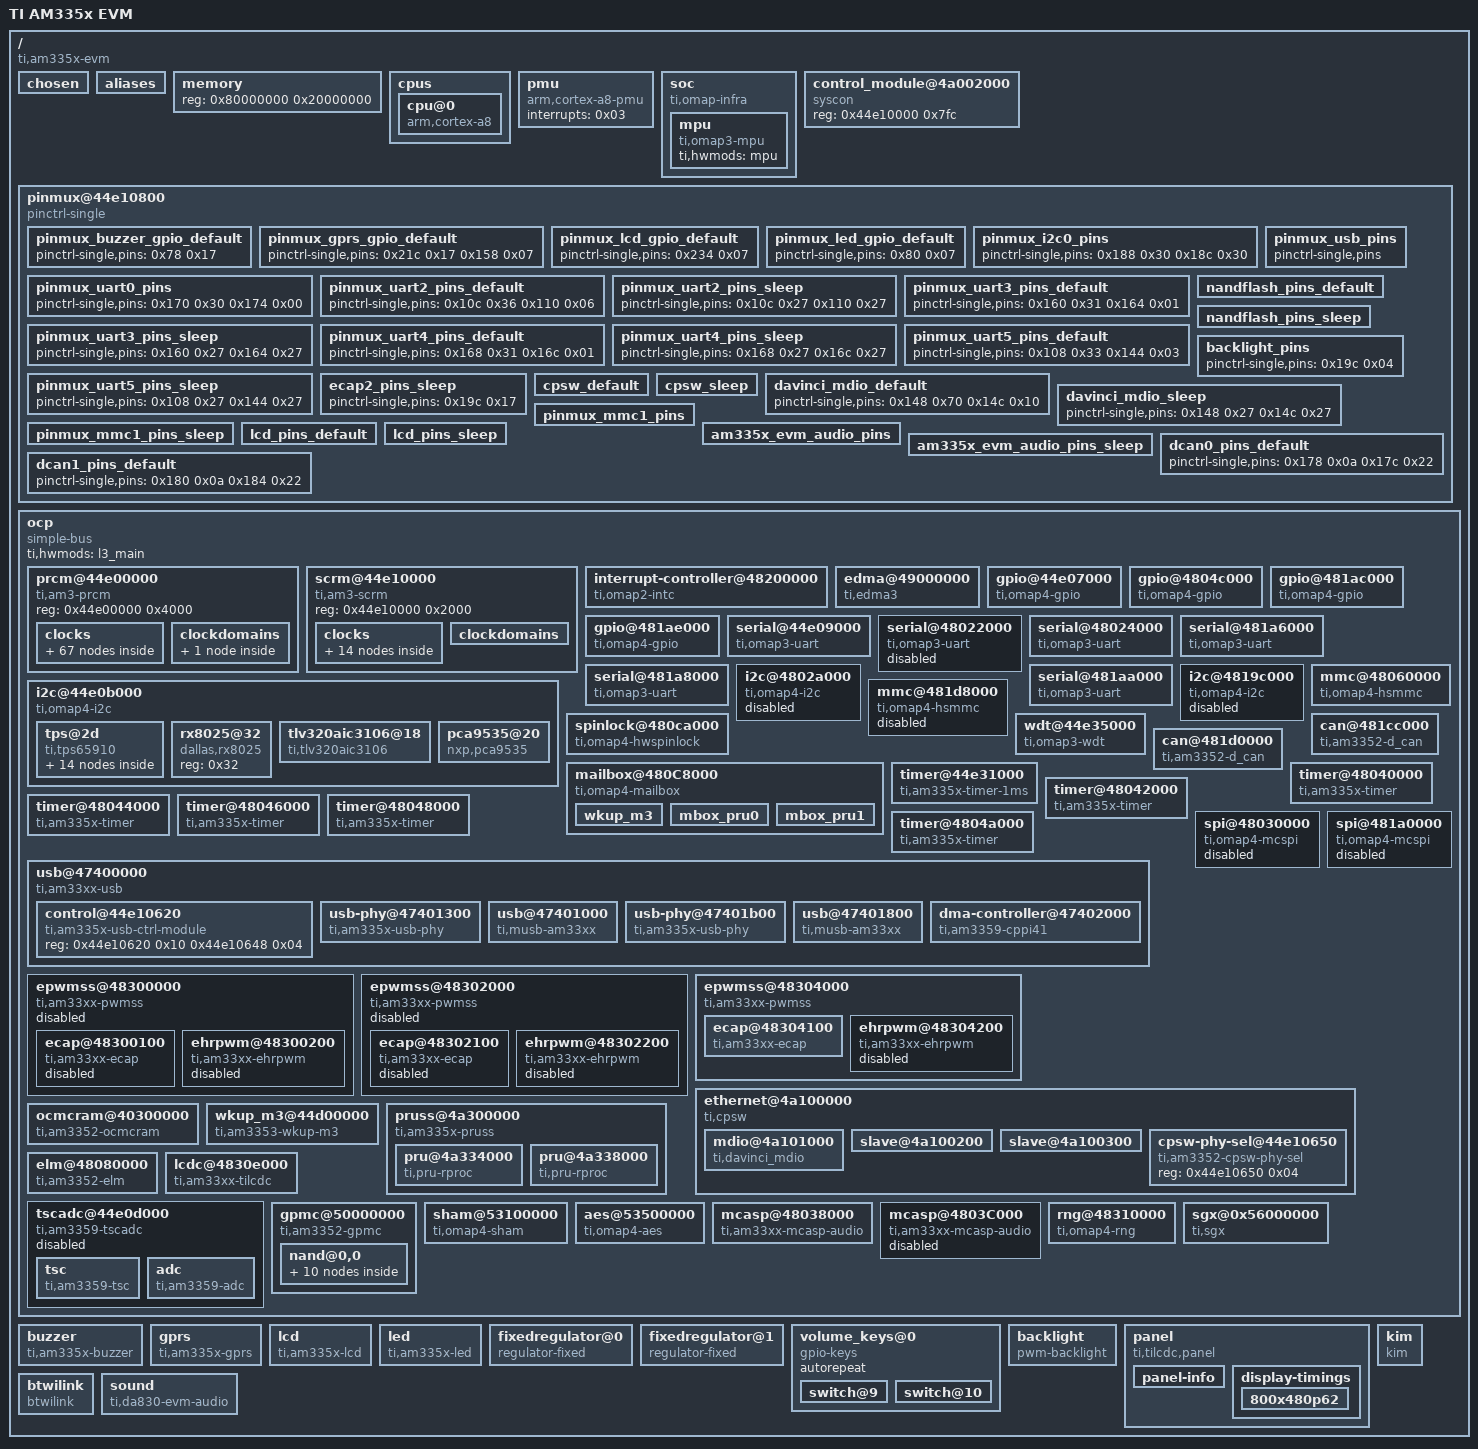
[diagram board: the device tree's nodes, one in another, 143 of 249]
/dts-v1/;

/ {
	#address-cells = <0x01>;
	#size-cells = <0x01>;
	compatible = "ti,am335x-evm", "ti,am33xx";
	interrupt-parent = <0x01>;
	model = "TI AM335x EVM";

	chosen {
	};

	aliases {
		i2c1 = "/ocp/i2c@44e0b000";
		i2c0 = "/ocp/i2c@4802a000";
		i2c2 = "/ocp/i2c@4819c000";
		serial0 = "/ocp/serial@44e09000";
		serial1 = "/ocp/serial@48022000";
		serial2 = "/ocp/serial@48024000";
		serial3 = "/ocp/serial@481a6000";
		serial4 = "/ocp/serial@481a8000";
		serial5 = "/ocp/serial@481aa000";
		d_can0 = "/ocp/can@481cc000";
		d_can1 = "/ocp/can@481d0000";
		usb0 = "/ocp/usb@47400000/usb@47401000";
		usb1 = "/ocp/usb@47400000/usb@47401800";
		phy0 = "/ocp/usb@47400000/usb-phy@47401300";
		phy1 = "/ocp/usb@47400000/usb-phy@47401b00";
		ethernet0 = "/ocp/ethernet@4a100000/slave@4a100200";
		ethernet1 = "/ocp/ethernet@4a100000/slave@4a100300";
	};

	memory {
		device_type = "memory";
		reg = <0x80000000 0x20000000>;
	};

	cpus {
		#address-cells = <0x01>;
		#size-cells = <0x00>;

		cpu@0 {
			compatible = "arm,cortex-a8";
			device_type = "cpu";
			reg = <0x00>;
			voltage-tolerance = <0x02>;
			clocks = <0x02>;
			clock-names = "cpu";
			clock-latency = <0x493e0>;
			cpu0-supply = <0x03>;
		};
	};

	pmu {
		compatible = "arm,cortex-a8-pmu";
		interrupts = <0x03>;
	};

	soc {
		compatible = "ti,omap-infra";

		mpu {
			compatible = "ti,omap3-mpu";
			ti,hwmods = "mpu";
		};
	};

	control_module@4a002000 {
		compatible = "syscon";
		reg = <0x44e10000 0x7fc>;
		linux,phandle = <0x36>;
		phandle = <0x36>;
	};

	pinmux@44e10800 {
		compatible = "pinctrl-single";
		reg = <0x44e10800 0x238>;
		#address-cells = <0x01>;
		#size-cells = <0x00>;
		pinctrl-single,register-width = <0x20>;
		pinctrl-single,function-mask = <0x7f>;

		pinmux_buzzer_gpio_default {
			pinctrl-single,pins = <0x78 0x17>;
			linux,phandle = <0x53>;
			phandle = <0x53>;
		};

		pinmux_gprs_gpio_default {
			pinctrl-single,pins = <0x21c 0x17 0x158 0x07>;
			linux,phandle = <0x55>;
			phandle = <0x55>;
		};

		pinmux_lcd_gpio_default {
			pinctrl-single,pins = <0x234 0x07>;
			linux,phandle = <0x56>;
			phandle = <0x56>;
		};

		pinmux_led_gpio_default {
			pinctrl-single,pins = <0x80 0x07>;
			linux,phandle = <0x57>;
			phandle = <0x57>;
		};

		pinmux_i2c0_pins {
			pinctrl-single,pins = <0x188 0x30 0x18c 0x30>;
			linux,phandle = <0x2e>;
			phandle = <0x2e>;
		};

		pinmux_usb_pins {
			pinctrl-single,pins;
		};

		pinmux_uart0_pins {
			pinctrl-single,pins = <0x170 0x30 0x174 0x00>;
			linux,phandle = <0x25>;
			phandle = <0x25>;
		};

		pinmux_uart2_pins_default {
			pinctrl-single,pins = <0x10c 0x36 0x110 0x06>;
			linux,phandle = <0x26>;
			phandle = <0x26>;
		};

		pinmux_uart2_pins_sleep {
			pinctrl-single,pins = <0x10c 0x27 0x110 0x27>;
			linux,phandle = <0x27>;
			phandle = <0x27>;
		};

		pinmux_uart3_pins_default {
			pinctrl-single,pins = <0x160 0x31 0x164 0x01>;
			linux,phandle = <0x28>;
			phandle = <0x28>;
		};

		pinmux_uart3_pins_sleep {
			pinctrl-single,pins = <0x160 0x27 0x164 0x27>;
			linux,phandle = <0x29>;
			phandle = <0x29>;
		};

		pinmux_uart4_pins_default {
			pinctrl-single,pins = <0x168 0x31 0x16c 0x01>;
			linux,phandle = <0x2a>;
			phandle = <0x2a>;
		};

		pinmux_uart4_pins_sleep {
			pinctrl-single,pins = <0x168 0x27 0x16c 0x27>;
			linux,phandle = <0x2b>;
			phandle = <0x2b>;
		};

		pinmux_uart5_pins_default {
			pinctrl-single,pins = <0x108 0x33 0x144 0x03>;
			linux,phandle = <0x2c>;
			phandle = <0x2c>;
		};

		pinmux_uart5_pins_sleep {
			pinctrl-single,pins = <0x108 0x27 0x144 0x27>;
			linux,phandle = <0x2d>;
			phandle = <0x2d>;
		};

		nandflash_pins_default {
			pinctrl-single,pins = <0x00 0x30 0x04 0x30 0x08 0x30 0x0c 0x30 0x10 0x30 0x14 0x30 0x18 0x30 0x1c 0x30 0x70 0x30 0x74 0x37 0x7c 0x08 0x90 0x08 0x94 0x08 0x98 0x08 0x9c 0x08>;
			linux,phandle = <0x4d>;
			phandle = <0x4d>;
		};

		nandflash_pins_sleep {
			pinctrl-single,pins = <0x00 0x27 0x04 0x27 0x08 0x27 0x0c 0x27 0x10 0x27 0x14 0x27 0x18 0x27 0x1c 0x27 0x70 0x27 0x74 0x27 0x7c 0x27 0x90 0x27 0x94 0x27 0x98 0x27 0x9c 0x27>;
			linux,phandle = <0x4e>;
			phandle = <0x4e>;
		};

		backlight_pins {
			pinctrl-single,pins = <0x19c 0x04>;
			linux,phandle = <0x3e>;
			phandle = <0x3e>;
		};

		ecap2_pins_sleep {
			pinctrl-single,pins = <0x19c 0x17>;
			linux,phandle = <0x3f>;
			phandle = <0x3f>;
		};

		cpsw_default {
			pinctrl-single,pins = <0x114 0x02 0x118 0x22 0x11c 0x02 0x120 0x02 0x124 0x02 0x128 0x02 0x12c 0x02 0x130 0x22 0x134 0x22 0x138 0x22 0x13c 0x22 0x140 0x22 0x40 0x02 0x44 0x22 0x48 0x02 0x4c 0x02 0x50 0x02 0x54 0x02 0x58 0x02 0x5c 0x22 0x60 0x22 0x64 0x22 0x68 0x22 0x6c 0x22>;
			linux,phandle = <0x42>;
			phandle = <0x42>;
		};

		cpsw_sleep {
			pinctrl-single,pins = <0x114 0x27 0x118 0x27 0x11c 0x27 0x120 0x27 0x124 0x27 0x128 0x27 0x12c 0x27 0x130 0x27 0x134 0x27 0x138 0x27 0x13c 0x27 0x140 0x27 0x40 0x27 0x44 0x27 0x48 0x27 0x4c 0x27 0x50 0x27 0x54 0x27 0x58 0x27 0x5c 0x27 0x60 0x27 0x64 0x27 0x68 0x27 0x6c 0x27>;
			linux,phandle = <0x43>;
			phandle = <0x43>;
		};

		davinci_mdio_default {
			pinctrl-single,pins = <0x148 0x70 0x14c 0x10>;
			linux,phandle = <0x44>;
			phandle = <0x44>;
		};

		davinci_mdio_sleep {
			pinctrl-single,pins = <0x148 0x27 0x14c 0x27>;
			linux,phandle = <0x45>;
			phandle = <0x45>;
		};

		pinmux_mmc1_pins {
			pinctrl-single,pins = <0xf0 0x30 0xf4 0x30 0xf8 0x30 0xfc 0x30 0x100 0x30 0x104 0x30 0x1e8 0x2f>;
			linux,phandle = <0x32>;
			phandle = <0x32>;
		};

		pinmux_mmc1_pins_sleep {
			pinctrl-single,pins = <0xf0 0x27 0xf4 0x27 0xf8 0x27 0xfc 0x27 0x100 0x27 0x104 0x27>;
			linux,phandle = <0x33>;
			phandle = <0x33>;
		};

		lcd_pins_default {
			pinctrl-single,pins = <0x20 0x01 0x24 0x01 0x28 0x01 0x2c 0x01 0x30 0x01 0x34 0x01 0x38 0x01 0x3c 0x01 0xa0 0x00 0xa4 0x00 0xa8 0x00 0xac 0x00 0xb0 0x00 0xb4 0x00 0xb8 0x00 0xbc 0x00 0xc0 0x00 0xc4 0x00 0xc8 0x00 0xcc 0x00 0xd0 0x00 0xd4 0x00 0xd8 0x00 0xdc 0x00 0xe0 0x00 0xe4 0x00 0xe8 0x00 0xec 0x00>;
			linux,phandle = <0x4b>;
			phandle = <0x4b>;
		};

		lcd_pins_sleep {
			pinctrl-single,pins = <0x20 0x27 0x24 0x27 0x28 0x27 0x2c 0x27 0x30 0x27 0x34 0x27 0x38 0x27 0x3c 0x27 0xa0 0x0f 0xa4 0x0f 0xa8 0x0f 0xac 0x0f 0xb0 0x0f 0xb4 0x0f 0xb8 0x0f 0xbc 0x0f 0xc0 0x0f 0xc4 0x0f 0xc8 0x0f 0xcc 0x0f 0xd0 0x0f 0xd4 0x0f 0xd8 0x0f 0xdc 0x0f 0xe0 0x27 0xe4 0x27 0xe8 0x27 0xec 0x27>;
			linux,phandle = <0x4c>;
			phandle = <0x4c>;
		};

		am335x_evm_audio_pins {
			pinctrl-single,pins = <0x190 0x20 0x194 0x20 0x198 0x20 0x1a8 0x20 0x1ac 0x08>;
			linux,phandle = <0x50>;
			phandle = <0x50>;
		};

		am335x_evm_audio_pins_sleep {
			pinctrl-single,pins = <0x190 0x27 0x194 0x27 0x198 0x27 0x1a8 0x27 0x1ac 0x27>;
			linux,phandle = <0x51>;
			phandle = <0x51>;
		};

		dcan0_pins_default {
			pinctrl-single,pins = <0x178 0x0a 0x17c 0x22>;
			linux,phandle = <0x37>;
			phandle = <0x37>;
		};

		dcan1_pins_default {
			pinctrl-single,pins = <0x180 0x0a 0x184 0x22>;
			linux,phandle = <0x39>;
			phandle = <0x39>;
		};
	};

	ocp {
		compatible = "simple-bus";
		#address-cells = <0x01>;
		#size-cells = <0x01>;
		ranges;
		ti,hwmods = "l3_main";

		prcm@44e00000 {
			compatible = "ti,am3-prcm";
			reg = <0x44e00000 0x4000>;

			clocks {
				#address-cells = <0x01>;
				#size-cells = <0x00>;

				clk_32768_ck {
					#clock-cells = <0x00>;
					compatible = "fixed-clock";
					clock-frequency = <0x8000>;
					linux,phandle = <0x14>;
					phandle = <0x14>;
				};

				clk_rc32k_ck {
					#clock-cells = <0x00>;
					compatible = "fixed-clock";
					clock-frequency = <0x7d00>;
					linux,phandle = <0x13>;
					phandle = <0x13>;
				};

				virt_19200000_ck {
					#clock-cells = <0x00>;
					compatible = "fixed-clock";
					clock-frequency = <0x124f800>;
					linux,phandle = <0x20>;
					phandle = <0x20>;
				};

				virt_24000000_ck {
					#clock-cells = <0x00>;
					compatible = "fixed-clock";
					clock-frequency = <0x16e3600>;
					linux,phandle = <0x21>;
					phandle = <0x21>;
				};

				virt_25000000_ck {
					#clock-cells = <0x00>;
					compatible = "fixed-clock";
					clock-frequency = <0x17d7840>;
					linux,phandle = <0x22>;
					phandle = <0x22>;
				};

				virt_26000000_ck {
					#clock-cells = <0x00>;
					compatible = "fixed-clock";
					clock-frequency = <0x18cba80>;
					linux,phandle = <0x23>;
					phandle = <0x23>;
				};

				tclkin_ck {
					#clock-cells = <0x00>;
					compatible = "fixed-clock";
					clock-frequency = <0xb71b00>;
					linux,phandle = <0x12>;
					phandle = <0x12>;
				};

				dpll_core_ck {
					#clock-cells = <0x00>;
					compatible = "ti,am3-dpll-core-clock";
					clocks = <0x04 0x04>;
					reg = <0x490 0x45c 0x468>;
					linux,phandle = <0x05>;
					phandle = <0x05>;
				};

				dpll_core_x2_ck {
					#clock-cells = <0x00>;
					compatible = "ti,am3-dpll-x2-clock";
					clocks = <0x05>;
					linux,phandle = <0x06>;
					phandle = <0x06>;
				};

				dpll_core_m4_ck {
					#clock-cells = <0x00>;
					compatible = "ti,divider-clock";
					clocks = <0x06>;
					ti,max-div = <0x1f>;
					reg = <0x480>;
					ti,index-starts-at-one;
					linux,phandle = <0x0e>;
					phandle = <0x0e>;
				};

				dpll_core_m5_ck {
					#clock-cells = <0x00>;
					compatible = "ti,divider-clock";
					clocks = <0x06>;
					ti,max-div = <0x1f>;
					reg = <0x484>;
					ti,index-starts-at-one;
					linux,phandle = <0x16>;
					phandle = <0x16>;
				};

				dpll_core_m6_ck {
					#clock-cells = <0x00>;
					compatible = "ti,divider-clock";
					clocks = <0x06>;
					ti,max-div = <0x1f>;
					reg = <0x4d8>;
					ti,index-starts-at-one;
				};

				dpll_mpu_ck {
					#clock-cells = <0x00>;
					compatible = "ti,am3-dpll-clock";
					clocks = <0x04 0x04>;
					reg = <0x488 0x420 0x42c>;
					linux,phandle = <0x02>;
					phandle = <0x02>;
				};

				dpll_mpu_m2_ck {
					#clock-cells = <0x00>;
					compatible = "ti,divider-clock";
					clocks = <0x02>;
					ti,max-div = <0x1f>;
					reg = <0x4a8>;
					ti,index-starts-at-one;
				};

				dpll_ddr_ck {
					#clock-cells = <0x00>;
					compatible = "ti,am3-dpll-no-gate-clock";
					clocks = <0x04 0x04>;
					reg = <0x494 0x434 0x440>;
					linux,phandle = <0x07>;
					phandle = <0x07>;
				};

				dpll_ddr_m2_ck {
					#clock-cells = <0x00>;
					compatible = "ti,divider-clock";
					clocks = <0x07>;
					ti,max-div = <0x1f>;
					reg = <0x4a0>;
					ti,index-starts-at-one;
					linux,phandle = <0x08>;
					phandle = <0x08>;
				};

				dpll_ddr_m2_div2_ck {
					#clock-cells = <0x00>;
					compatible = "fixed-factor-clock";
					clocks = <0x08>;
					clock-mult = <0x01>;
					clock-div = <0x02>;
				};

				dpll_disp_ck {
					#clock-cells = <0x00>;
					compatible = "ti,am3-dpll-no-gate-clock";
					clocks = <0x04 0x04>;
					reg = <0x498 0x448 0x454>;
					linux,phandle = <0x09>;
					phandle = <0x09>;
				};

				dpll_disp_m2_ck {
					#clock-cells = <0x00>;
					compatible = "ti,divider-clock";
					clocks = <0x09>;
					ti,max-div = <0x1f>;
					reg = <0x4a4>;
					ti,index-starts-at-one;
					ti,set-rate-parent;
					linux,phandle = <0x10>;
					phandle = <0x10>;
				};

				dpll_per_ck {
					#clock-cells = <0x00>;
					compatible = "ti,am3-dpll-no-gate-j-type-clock";
					clocks = <0x04 0x04>;
					reg = <0x48c 0x470 0x49c>;
					linux,phandle = <0x0a>;
					phandle = <0x0a>;
				};

				dpll_per_m2_ck {
					#clock-cells = <0x00>;
					compatible = "ti,divider-clock";
					clocks = <0x0a>;
					ti,max-div = <0x1f>;
					reg = <0x4ac>;
					ti,index-starts-at-one;
					linux,phandle = <0x0b>;
					phandle = <0x0b>;
				};

				dpll_per_m2_div4_wkupdm_ck {
					#clock-cells = <0x00>;
					compatible = "fixed-factor-clock";
					clocks = <0x0b>;
					clock-mult = <0x01>;
					clock-div = <0x04>;
				};

				dpll_per_m2_div4_ck {
					#clock-cells = <0x00>;
					compatible = "fixed-factor-clock";
					clocks = <0x0b>;
					clock-mult = <0x01>;
					clock-div = <0x04>;
				};

				cefuse_fck {
					#clock-cells = <0x00>;
					compatible = "ti,gate-clock";
					clocks = <0x04>;
					ti,bit-shift = <0x01>;
					reg = <0xa20>;
				};

				clk_24mhz {
					#clock-cells = <0x00>;
					compatible = "fixed-factor-clock";
					clocks = <0x0b>;
					clock-mult = <0x01>;
					clock-div = <0x08>;
					linux,phandle = <0x0c>;
					phandle = <0x0c>;
				};

				clkdiv32k_ck {
					#clock-cells = <0x00>;
					compatible = "fixed-factor-clock";
					clocks = <0x0c>;
					clock-mult = <0x01>;
					clock-div = <0x2dc>;
					linux,phandle = <0x0d>;
					phandle = <0x0d>;
				};

				clkdiv32k_ick {
					#clock-cells = <0x00>;
					compatible = "ti,gate-clock";
					clocks = <0x0d>;
					ti,bit-shift = <0x01>;
					reg = <0x14c>;
					linux,phandle = <0x11>;
					phandle = <0x11>;
				};

				l3_gclk {
					#clock-cells = <0x00>;
					compatible = "fixed-factor-clock";
					clocks = <0x0e>;
					clock-mult = <0x01>;
					clock-div = <0x01>;
					linux,phandle = <0x0f>;
					phandle = <0x0f>;
				};

				pruss_ocp_gclk {
					#clock-cells = <0x00>;
					compatible = "ti,mux-clock";
					clocks = <0x0f 0x10>;
					reg = <0x530>;
				};

				mmu_fck {
					#clock-cells = <0x00>;
					compatible = "ti,gate-clock";
					clocks = <0x0e>;
					ti,bit-shift = <0x01>;
					reg = <0x914>;
				};

				timer1_fck {
					#clock-cells = <0x00>;
					compatible = "ti,mux-clock";
					clocks = <0x04 0x11 0x12 0x13 0x14>;
					reg = <0x528>;
				};

				timer2_fck {
					#clock-cells = <0x00>;
					compatible = "ti,mux-clock";
					clocks = <0x12 0x04 0x11>;
					reg = <0x508>;
				};

				timer3_fck {
					#clock-cells = <0x00>;
					compatible = "ti,mux-clock";
					clocks = <0x12 0x04 0x11>;
					reg = <0x50c>;
				};

				timer4_fck {
					#clock-cells = <0x00>;
					compatible = "ti,mux-clock";
					clocks = <0x12 0x04 0x11>;
					reg = <0x510>;
				};

				timer5_fck {
					#clock-cells = <0x00>;
					compatible = "ti,mux-clock";
					clocks = <0x12 0x04 0x11>;
					reg = <0x518>;
				};

				timer6_fck {
					#clock-cells = <0x00>;
					compatible = "ti,mux-clock";
					clocks = <0x12 0x04 0x11>;
					reg = <0x51c>;
				};

				timer7_fck {
					#clock-cells = <0x00>;
					compatible = "ti,mux-clock";
					clocks = <0x12 0x04 0x11>;
					reg = <0x504>;
				};

				usbotg_fck {
					#clock-cells = <0x00>;
					compatible = "ti,gate-clock";
					clocks = <0x0a>;
					ti,bit-shift = <0x08>;
					reg = <0x47c>;
				};

				dpll_core_m4_div2_ck {
					#clock-cells = <0x00>;
					compatible = "fixed-factor-clock";
					clocks = <0x0e>;
					clock-mult = <0x01>;
					clock-div = <0x02>;
					linux,phandle = <0x15>;
					phandle = <0x15>;
				};

				ieee5000_fck {
					#clock-cells = <0x00>;
					compatible = "ti,gate-clock";
					clocks = <0x15>;
					ti,bit-shift = <0x01>;
					reg = <0xe4>;
				};

				wdt1_fck {
					#clock-cells = <0x00>;
					compatible = "ti,mux-clock";
					clocks = <0x13 0x11>;
					reg = <0x538>;
				};

				l4_rtc_gclk {
					#clock-cells = <0x00>;
					compatible = "fixed-factor-clock";
					clocks = <0x0e>;
					clock-mult = <0x01>;
					clock-div = <0x02>;
				};

				l4hs_gclk {
					#clock-cells = <0x00>;
					compatible = "fixed-factor-clock";
					clocks = <0x0e>;
					clock-mult = <0x01>;
					clock-div = <0x01>;
				};

				l3s_gclk {
					#clock-cells = <0x00>;
					compatible = "fixed-factor-clock";
					clocks = <0x15>;
					clock-mult = <0x01>;
					clock-div = <0x01>;
				};

				l4fw_gclk {
					#clock-cells = <0x00>;
					compatible = "fixed-factor-clock";
					clocks = <0x15>;
					clock-mult = <0x01>;
					clock-div = <0x01>;
				};

				l4ls_gclk {
					#clock-cells = <0x00>;
					compatible = "fixed-factor-clock";
					clocks = <0x15>;
					clock-mult = <0x01>;
					clock-div = <0x01>;
				};

				sysclk_div_ck {
					#clock-cells = <0x00>;
					compatible = "fixed-factor-clock";
					clocks = <0x0e>;
					clock-mult = <0x01>;
					clock-div = <0x01>;
				};

				cpsw_125mhz_gclk {
					#clock-cells = <0x00>;
					compatible = "fixed-factor-clock";
					clocks = <0x16>;
					clock-mult = <0x01>;
					clock-div = <0x02>;
					linux,phandle = <0x40>;
					phandle = <0x40>;
				};

				cpsw_cpts_rft_clk {
					#clock-cells = <0x00>;
					compatible = "ti,mux-clock";
					clocks = <0x16 0x0e>;
					reg = <0x520>;
					linux,phandle = <0x41>;
					phandle = <0x41>;
				};

				gpio0_dbclk_mux_ck {
					#clock-cells = <0x00>;
					compatible = "ti,mux-clock";
					clocks = <0x13 0x14 0x11>;
					reg = <0x53c>;
					linux,phandle = <0x17>;
					phandle = <0x17>;
				};

				gpio0_dbclk {
					#clock-cells = <0x00>;
					compatible = "ti,gate-clock";
					clocks = <0x17>;
					ti,bit-shift = <0x12>;
					reg = <0x408>;
				};

				gpio1_dbclk {
					#clock-cells = <0x00>;
					compatible = "ti,gate-clock";
					clocks = <0x11>;
					ti,bit-shift = <0x12>;
					reg = <0xac>;
				};

				gpio2_dbclk {
					#clock-cells = <0x00>;
					compatible = "ti,gate-clock";
					clocks = <0x11>;
					ti,bit-shift = <0x12>;
					reg = <0xb0>;
				};

				gpio3_dbclk {
					#clock-cells = <0x00>;
					compatible = "ti,gate-clock";
					clocks = <0x11>;
					ti,bit-shift = <0x12>;
					reg = <0xb4>;
				};

				lcd_gclk {
					#clock-cells = <0x00>;
					compatible = "ti,mux-clock";
					clocks = <0x10 0x16 0x0b>;
					reg = <0x534>;
					ti,set-rate-parent;
					linux,phandle = <0x19>;
					phandle = <0x19>;
				};

				mmc_clk {
					#clock-cells = <0x00>;
					compatible = "fixed-factor-clock";
					clocks = <0x0b>;
					clock-mult = <0x01>;
					clock-div = <0x02>;
				};

				gfx_fclk_clksel_ck {
					#clock-cells = <0x00>;
					compatible = "ti,mux-clock";
					clocks = <0x0e 0x0b>;
					ti,bit-shift = <0x01>;
					reg = <0x52c>;
					linux,phandle = <0x18>;
					phandle = <0x18>;
				};

				gfx_fck_div_ck {
					#clock-cells = <0x00>;
					compatible = "ti,divider-clock";
					clocks = <0x18>;
					reg = <0x52c>;
					ti,max-div = <0x02>;
				};

				sysclkout_pre_ck {
					#clock-cells = <0x00>;
					compatible = "ti,mux-clock";
					clocks = <0x14 0x0f 0x08 0x0b 0x19>;
					reg = <0x700>;
					linux,phandle = <0x1a>;
					phandle = <0x1a>;
				};

				clkout2_div_ck {
					#clock-cells = <0x00>;
					compatible = "ti,divider-clock";
					clocks = <0x1a>;
					ti,bit-shift = <0x03>;
					ti,max-div = <0x08>;
					reg = <0x700>;
					linux,phandle = <0x1f>;
					phandle = <0x1f>;
				};

				dbg_sysclk_ck {
					#clock-cells = <0x00>;
					compatible = "ti,gate-clock";
					clocks = <0x04>;
					ti,bit-shift = <0x13>;
					reg = <0x414>;
					linux,phandle = <0x1b>;
					phandle = <0x1b>;
				};

				dbg_clka_ck {
					#clock-cells = <0x00>;
					compatible = "ti,gate-clock";
					clocks = <0x0e>;
					ti,bit-shift = <0x1e>;
					reg = <0x414>;
					linux,phandle = <0x1c>;
					phandle = <0x1c>;
				};

				stm_pmd_clock_mux_ck {
					#clock-cells = <0x00>;
					compatible = "ti,mux-clock";
					clocks = <0x1b 0x1c>;
					ti,bit-shift = <0x16>;
					reg = <0x414>;
					linux,phandle = <0x1d>;
					phandle = <0x1d>;
				};

				trace_pmd_clk_mux_ck {
					#clock-cells = <0x00>;
					compatible = "ti,mux-clock";
					clocks = <0x1b 0x1c>;
					ti,bit-shift = <0x14>;
					reg = <0x414>;
					linux,phandle = <0x1e>;
					phandle = <0x1e>;
				};

				stm_clk_div_ck {
					#clock-cells = <0x00>;
					compatible = "ti,divider-clock";
					clocks = <0x1d>;
					ti,bit-shift = <0x1b>;
					ti,max-div = <0x40>;
					reg = <0x414>;
					ti,index-power-of-two;
				};

				trace_clk_div_ck {
					#clock-cells = <0x00>;
					compatible = "ti,divider-clock";
					clocks = <0x1e>;
					ti,bit-shift = <0x18>;
					ti,max-div = <0x40>;
					reg = <0x414>;
					ti,index-power-of-two;
				};

				clkout2_ck {
					#clock-cells = <0x00>;
					compatible = "ti,gate-clock";
					clocks = <0x1f>;
					ti,bit-shift = <0x07>;
					reg = <0x700>;
				};
			};

			clockdomains {

				clk_24mhz_clkdm {
					compatible = "ti,clockdomain";
					clocks = <0x11>;
				};
			};
		};

		scrm@44e10000 {
			compatible = "ti,am3-scrm";
			reg = <0x44e10000 0x2000>;

			clocks {
				#address-cells = <0x01>;
				#size-cells = <0x00>;

				sys_clkin_ck {
					#clock-cells = <0x00>;
					compatible = "ti,mux-clock";
					clocks = <0x20 0x21 0x22 0x23>;
					ti,bit-shift = <0x16>;
					reg = <0x40>;
					linux,phandle = <0x04>;
					phandle = <0x04>;
				};

				adc_tsc_fck {
					#clock-cells = <0x00>;
					compatible = "fixed-factor-clock";
					clocks = <0x04>;
					clock-mult = <0x01>;
					clock-div = <0x01>;
				};

				dcan0_fck {
					#clock-cells = <0x00>;
					compatible = "fixed-factor-clock";
					clocks = <0x04>;
					clock-mult = <0x01>;
					clock-div = <0x01>;
					linux,phandle = <0x35>;
					phandle = <0x35>;
				};

				dcan1_fck {
					#clock-cells = <0x00>;
					compatible = "fixed-factor-clock";
					clocks = <0x04>;
					clock-mult = <0x01>;
					clock-div = <0x01>;
					linux,phandle = <0x38>;
					phandle = <0x38>;
				};

				mcasp0_fck {
					#clock-cells = <0x00>;
					compatible = "fixed-factor-clock";
					clocks = <0x04>;
					clock-mult = <0x01>;
					clock-div = <0x01>;
				};

				mcasp1_fck {
					#clock-cells = <0x00>;
					compatible = "fixed-factor-clock";
					clocks = <0x04>;
					clock-mult = <0x01>;
					clock-div = <0x01>;
				};

				smartreflex0_fck {
					#clock-cells = <0x00>;
					compatible = "fixed-factor-clock";
					clocks = <0x04>;
					clock-mult = <0x01>;
					clock-div = <0x01>;
				};

				smartreflex1_fck {
					#clock-cells = <0x00>;
					compatible = "fixed-factor-clock";
					clocks = <0x04>;
					clock-mult = <0x01>;
					clock-div = <0x01>;
				};

				sha0_fck {
					#clock-cells = <0x00>;
					compatible = "fixed-factor-clock";
					clocks = <0x04>;
					clock-mult = <0x01>;
					clock-div = <0x01>;
				};

				aes0_fck {
					#clock-cells = <0x00>;
					compatible = "fixed-factor-clock";
					clocks = <0x04>;
					clock-mult = <0x01>;
					clock-div = <0x01>;
				};

				rng_fck {
					#clock-cells = <0x00>;
					compatible = "fixed-factor-clock";
					clocks = <0x04>;
					clock-mult = <0x01>;
					clock-div = <0x01>;
				};

				ehrpwm0_tbclk@44e10664 {
					#clock-cells = <0x00>;
					compatible = "ti,gate-clock";
					clocks = <0x0b>;
					ti,bit-shift = <0x00>;
					reg = <0x664>;
				};

				ehrpwm1_tbclk@44e10664 {
					#clock-cells = <0x00>;
					compatible = "ti,gate-clock";
					clocks = <0x0b>;
					ti,bit-shift = <0x01>;
					reg = <0x664>;
				};

				ehrpwm2_tbclk@44e10664 {
					#clock-cells = <0x00>;
					compatible = "ti,gate-clock";
					clocks = <0x0b>;
					ti,bit-shift = <0x02>;
					reg = <0x664>;
				};
			};

			clockdomains {
			};
		};

		interrupt-controller@48200000 {
			compatible = "ti,omap2-intc";
			interrupt-controller;
			#interrupt-cells = <0x01>;
			ti,intc-size = <0x80>;
			reg = <0x48200000 0x1000>;
			linux,phandle = <0x01>;
			phandle = <0x01>;
		};

		edma@49000000 {
			compatible = "ti,edma3";
			ti,hwmods = "tpcc", "tptc0", "tptc1", "tptc2";
			reg = <0x49000000 0x10000 0x44e10f90 0x40>;
			interrupts = <0x0c 0x0d 0x0e>;
			#dma-cells = <0x01>;
			ti,edma-xbar-event-map = <0x1000c 0x2000d>;
			linux,phandle = <0x24>;
			phandle = <0x24>;
		};

		gpio@44e07000 {
			compatible = "ti,omap4-gpio";
			ti,hwmods = "gpio1";
			gpio-controller;
			#gpio-cells = <0x02>;
			interrupt-controller;
			#interrupt-cells = <0x02>;
			reg = <0x44e07000 0x1000>;
			interrupts = <0x60>;
			linux,phandle = <0x54>;
			phandle = <0x54>;
		};

		gpio@4804c000 {
			compatible = "ti,omap4-gpio";
			ti,hwmods = "gpio2";
			gpio-controller;
			#gpio-cells = <0x02>;
			interrupt-controller;
			#interrupt-cells = <0x02>;
			reg = <0x4804c000 0x1000>;
			interrupts = <0x62>;
			linux,phandle = <0x52>;
			phandle = <0x52>;
		};

		gpio@481ac000 {
			compatible = "ti,omap4-gpio";
			ti,hwmods = "gpio3";
			gpio-controller;
			#gpio-cells = <0x02>;
			interrupt-controller;
			#interrupt-cells = <0x02>;
			reg = <0x481ac000 0x1000>;
			interrupts = <0x20>;
		};

		gpio@481ae000 {
			compatible = "ti,omap4-gpio";
			ti,hwmods = "gpio4";
			gpio-controller;
			#gpio-cells = <0x02>;
			interrupt-controller;
			#interrupt-cells = <0x02>;
			reg = <0x481ae000 0x1000>;
			interrupts = <0x3e>;
			linux,phandle = <0x34>;
			phandle = <0x34>;
		};

		serial@44e09000 {
			compatible = "ti,omap3-uart";
			ti,hwmods = "uart1";
			clock-frequency = <0x2dc6c00>;
			reg = <0x44e09000 0x2000>;
			interrupts = <0x48>;
			status = "okay";
			dmas = <0x24 0x1a 0x24 0x1b>;
			dma-names = "tx", "rx";
			pinctrl-names = "default";
			pinctrl-0 = <0x25>;
		};

		serial@48022000 {
			compatible = "ti,omap3-uart";
			ti,hwmods = "uart2";
			clock-frequency = <0x2dc6c00>;
			reg = <0x48022000 0x2000>;
			interrupts = <0x49>;
			status = "disabled";
			dmas = <0x24 0x1c 0x24 0x1d>;
			dma-names = "tx", "rx";
		};

		serial@48024000 {
			compatible = "ti,omap3-uart";
			ti,hwmods = "uart3";
			clock-frequency = <0x2dc6c00>;
			reg = <0x48024000 0x2000>;
			interrupts = <0x4a>;
			status = "okay";
			dmas = <0x24 0x1e 0x24 0x1f>;
			dma-names = "tx", "rx";
			pinctrl-names = "default", "sleep";
			pinctrl-0 = <0x26>;
			pinctrl-1 = <0x27>;
		};

		serial@481a6000 {
			compatible = "ti,omap3-uart";
			ti,hwmods = "uart4";
			clock-frequency = <0x2dc6c00>;
			reg = <0x481a6000 0x2000>;
			interrupts = <0x2c>;
			status = "okay";
			pinctrl-names = "default", "sleep";
			pinctrl-0 = <0x28>;
			pinctrl-1 = <0x29>;
		};

		serial@481a8000 {
			compatible = "ti,omap3-uart";
			ti,hwmods = "uart5";
			clock-frequency = <0x2dc6c00>;
			reg = <0x481a8000 0x2000>;
			interrupts = <0x2d>;
			status = "okay";
			pinctrl-names = "default", "sleep";
			pinctrl-0 = <0x2a>;
			pinctrl-1 = <0x2b>;
		};

		serial@481aa000 {
			compatible = "ti,omap3-uart";
			ti,hwmods = "uart6";
			clock-frequency = <0x2dc6c00>;
			reg = <0x481aa000 0x2000>;
			interrupts = <0x2e>;
			status = "okay";
			pinctrl-names = "default", "sleep";
			pinctrl-0 = <0x2c>;
			pinctrl-1 = <0x2d>;
		};

		i2c@44e0b000 {
			compatible = "ti,omap4-i2c";
			#address-cells = <0x01>;
			#size-cells = <0x00>;
			ti,hwmods = "i2c1";
			reg = <0x44e0b000 0x1000>;
			interrupts = <0x46>;
			status = "okay";
			pinctrl-names = "default";
			pinctrl-0 = <0x2e>;
			clock-frequency = <0x61a80>;

			tps@2d {
				reg = <0x2d>;
				compatible = "ti,tps65910";
				vcc1-supply = <0x2f>;
				vcc2-supply = <0x2f>;
				vcc3-supply = <0x2f>;
				vcc4-supply = <0x2f>;
				vcc5-supply = <0x2f>;
				vcc6-supply = <0x2f>;
				vcc7-supply = <0x2f>;
				vccio-supply = <0x2f>;

				regulators {
					#address-cells = <0x01>;
					#size-cells = <0x00>;

					regulator@0 {
						reg = <0x00>;
						regulator-compatible = "vrtc";
						regulator-always-on;
					};

					regulator@1 {
						reg = <0x01>;
						regulator-compatible = "vio";
						regulator-always-on;
					};

					regulator@2 {
						reg = <0x02>;
						regulator-compatible = "vdd1";
						regulator-name = "vdd_mpu";
						regulator-min-microvolt = <0xdec74>;
						regulator-max-microvolt = <0x1506d0>;
						regulator-boot-on;
						regulator-always-on;
						linux,phandle = <0x03>;
						phandle = <0x03>;
					};

					regulator@3 {
						reg = <0x03>;
						regulator-compatible = "vdd2";
						regulator-name = "vdd_core";
						regulator-min-microvolt = <0xdec74>;
						regulator-max-microvolt = <0x118c30>;
						regulator-boot-on;
						regulator-always-on;
					};

					regulator@4 {
						reg = <0x04>;
						regulator-compatible = "vdd3";
						regulator-always-on;
					};

					regulator@5 {
						reg = <0x05>;
						regulator-compatible = "vdig1";
						regulator-always-on;
					};

					regulator@6 {
						reg = <0x06>;
						regulator-compatible = "vdig2";
						regulator-always-on;
					};

					regulator@7 {
						reg = <0x07>;
						regulator-compatible = "vpll";
						regulator-always-on;
					};

					regulator@8 {
						reg = <0x08>;
						regulator-compatible = "vdac";
						regulator-always-on;
					};

					regulator@9 {
						reg = <0x09>;
						regulator-compatible = "vaux1";
						regulator-always-on;
					};

					regulator@10 {
						reg = <0x0a>;
						regulator-compatible = "vaux2";
						regulator-always-on;
						linux,phandle = <0x30>;
						phandle = <0x30>;
					};

					regulator@11 {
						reg = <0x0b>;
						regulator-compatible = "vaux33";
						regulator-always-on;
					};

					regulator@12 {
						reg = <0x0c>;
						regulator-compatible = "vmmc";
						regulator-min-microvolt = <0x1b7740>;
						regulator-max-microvolt = <0x325aa0>;
						regulator-always-on;
						linux,phandle = <0x31>;
						phandle = <0x31>;
					};
				};
			};

			rx8025@32 {
				compatible = "dallas,rx8025";
				reg = <0x32>;
				status = "okay";
			};

			tlv320aic3106@18 {
				compatible = "ti,tlv320aic3106";
				reg = <0x18>;
				status = "okay";
				AVDD-supply = <0x30>;
				IOVDD-supply = <0x30>;
				DRVDD-supply = <0x30>;
				DVDD-supply = <0x2f>;
				linux,phandle = <0x59>;
				phandle = <0x59>;
			};

			pca9535@20 {
				compatible = "nxp,pca9535";
				gpio-controller;
				#gpio-cells = <0x02>;
				reg = <0x20>;
			};
		};

		i2c@4802a000 {
			compatible = "ti,omap4-i2c";
			#address-cells = <0x01>;
			#size-cells = <0x00>;
			ti,hwmods = "i2c2";
			reg = <0x4802a000 0x1000>;
			interrupts = <0x47>;
			status = "disabled";
		};

		i2c@4819c000 {
			compatible = "ti,omap4-i2c";
			#address-cells = <0x01>;
			#size-cells = <0x00>;
			ti,hwmods = "i2c3";
			reg = <0x4819c000 0x1000>;
			interrupts = <0x1e>;
			status = "disabled";
		};

		mmc@48060000 {
			compatible = "ti,omap4-hsmmc";
			ti,hwmods = "mmc1";
			ti,dual-volt;
			ti,needs-special-reset;
			ti,needs-special-hs-handling;
			dmas = <0x24 0x18 0x24 0x19>;
			dma-names = "tx", "rx";
			interrupts = <0x40>;
			interrupt-parent = <0x01>;
			reg = <0x48060000 0x1000>;
			status = "okay";
			vmmc-supply = <0x31>;
			bus-width = <0x04>;
			pinctrl-names = "default", "sleep";
			pinctrl-0 = <0x32>;
			pinctrl-1 = <0x33>;
			cd-gpios = <0x34 0x08 0x00>;
		};

		mmc@481d8000 {
			compatible = "ti,omap4-hsmmc";
			ti,hwmods = "mmc2";
			ti,needs-special-reset;
			dmas = <0x24 0x02 0x24 0x03>;
			dma-names = "tx", "rx";
			interrupts = <0x1c>;
			interrupt-parent = <0x01>;
			reg = <0x481d8000 0x1000>;
			status = "disabled";
		};

		spinlock@480ca000 {
			compatible = "ti,omap4-hwspinlock";
			reg = <0x480ca000 0x1000>;
			ti,hwmods = "spinlock";
			#hwlock-cells = <0x01>;
		};

		wdt@44e35000 {
			compatible = "ti,omap3-wdt";
			ti,hwmods = "wd_timer2";
			reg = <0x44e35000 0x1000>;
			interrupts = <0x5b>;
		};

		can@481cc000 {
			compatible = "ti,am3352-d_can";
			ti,hwmods = "d_can0";
			clocks = <0x35>;
			clock-names = "fck";
			reg = <0x481cc000 0x2000>;
			syscon-raminit = <0x36 0x644 0x00>;
			interrupts = <0x34>;
			status = "okay";
			pinctrl-names = "default";
			pinctrl-0 = <0x37>;
		};

		can@481d0000 {
			compatible = "ti,am3352-d_can";
			ti,hwmods = "d_can1";
			clocks = <0x38>;
			clock-names = "fck";
			reg = <0x481d0000 0x2000>;
			syscon-raminit = <0x36 0x644 0x01>;
			interrupts = <0x37>;
			status = "okay";
			pinctrl-names = "default";
			pinctrl-0 = <0x39>;
		};

		mailbox@480C8000 {
			compatible = "ti,omap4-mailbox";
			reg = <0x480c8000 0x200>;
			interrupts = <0x4d>;
			ti,hwmods = "mailbox";
			#mbox-cells = <0x01>;
			ti,mbox-num-users = <0x04>;
			ti,mbox-num-fifos = <0x08>;
			linux,phandle = <0x47>;
			phandle = <0x47>;

			wkup_m3 {
				ti,mbox-send-noirq;
				ti,mbox-tx = <0x00 0x00 0x00>;
				ti,mbox-rx = <0x00 0x00 0x03>;
				linux,phandle = <0x48>;
				phandle = <0x48>;
			};

			mbox_pru0 {
				ti,mbox-tx = <0x02 0x00 0x00>;
				ti,mbox-rx = <0x03 0x00 0x00>;
				linux,phandle = <0x49>;
				phandle = <0x49>;
			};

			mbox_pru1 {
				ti,mbox-tx = <0x04 0x00 0x00>;
				ti,mbox-rx = <0x05 0x00 0x00>;
				linux,phandle = <0x4a>;
				phandle = <0x4a>;
			};
		};

		timer@44e31000 {
			compatible = "ti,am335x-timer-1ms";
			reg = <0x44e31000 0x400>;
			interrupts = <0x43>;
			ti,hwmods = "timer1";
			ti,timer-alwon;
		};

		timer@48040000 {
			compatible = "ti,am335x-timer";
			reg = <0x48040000 0x400>;
			interrupts = <0x44>;
			ti,hwmods = "timer2";
		};

		timer@48042000 {
			compatible = "ti,am335x-timer";
			reg = <0x48042000 0x400>;
			interrupts = <0x45>;
			ti,hwmods = "timer3";
		};

		timer@48044000 {
			compatible = "ti,am335x-timer";
			reg = <0x48044000 0x400>;
			interrupts = <0x5c>;
			ti,hwmods = "timer4";
			ti,timer-pwm;
		};

		timer@48046000 {
			compatible = "ti,am335x-timer";
			reg = <0x48046000 0x400>;
			interrupts = <0x5d>;
			ti,hwmods = "timer5";
			ti,timer-pwm;
		};

		timer@48048000 {
			compatible = "ti,am335x-timer";
			reg = <0x48048000 0x400>;
			interrupts = <0x5e>;
			ti,hwmods = "timer6";
			ti,timer-pwm;
		};

		timer@4804a000 {
			compatible = "ti,am335x-timer";
			reg = <0x4804a000 0x400>;
			interrupts = <0x5f>;
			ti,hwmods = "timer7";
			ti,timer-pwm;
		};

		spi@48030000 {
			compatible = "ti,omap4-mcspi";
			#address-cells = <0x01>;
			#size-cells = <0x00>;
			reg = <0x48030000 0x400>;
			interrupts = <0x41>;
			ti,spi-num-cs = <0x02>;
			ti,hwmods = "spi0";
			dmas = <0x24 0x10 0x24 0x11 0x24 0x12 0x24 0x13>;
			dma-names = "tx0", "rx0", "tx1", "rx1";
			status = "disabled";
		};

		spi@481a0000 {
			compatible = "ti,omap4-mcspi";
			#address-cells = <0x01>;
			#size-cells = <0x00>;
			reg = <0x481a0000 0x400>;
			interrupts = <0x7d>;
			ti,spi-num-cs = <0x02>;
			ti,hwmods = "spi1";
			dmas = <0x24 0x2a 0x24 0x2b 0x24 0x2c 0x24 0x2d>;
			dma-names = "tx0", "rx0", "tx1", "rx1";
			status = "disabled";
		};

		usb@47400000 {
			compatible = "ti,am33xx-usb";
			reg = <0x47400000 0x1000>;
			ranges;
			#address-cells = <0x01>;
			#size-cells = <0x01>;
			ti,hwmods = "usb_otg_hs";
			status = "okay";
			pinctrl-names = "default";

			control@44e10620 {
				compatible = "ti,am335x-usb-ctrl-module";
				reg = <0x44e10620 0x10 0x44e10648 0x04>;
				reg-names = "phy_ctrl", "wakeup";
				status = "okay";
				linux,phandle = <0x3a>;
				phandle = <0x3a>;
			};

			usb-phy@47401300 {
				compatible = "ti,am335x-usb-phy";
				reg = <0x47401300 0x100>;
				reg-names = "phy";
				status = "okay";
				ti,ctrl_mod = <0x3a>;
				linux,phandle = <0x3b>;
				phandle = <0x3b>;
			};

			usb@47401000 {
				compatible = "ti,musb-am33xx";
				status = "okay";
				reg = <0x47401400 0x400 0x47401000 0x200>;
				reg-names = "mc", "control";
				interrupts = <0x12>;
				interrupt-names = "mc";
				dr_mode = "otg";
				mentor,multipoint = <0x01>;
				mentor,num-eps = <0x10>;
				mentor,ram-bits = <0x0c>;
				mentor,power = <0x1f4>;
				phys = <0x3b>;
				dmas = <0x3c 0x00 0x00 0x3c 0x01 0x00 0x3c 0x02 0x00 0x3c 0x03 0x00 0x3c 0x04 0x00 0x3c 0x05 0x00 0x3c 0x06 0x00 0x3c 0x07 0x00 0x3c 0x08 0x00 0x3c 0x09 0x00 0x3c 0x0a 0x00 0x3c 0x0b 0x00 0x3c 0x0c 0x00 0x3c 0x0d 0x00 0x3c 0x0e 0x00 0x3c 0x00 0x01 0x3c 0x01 0x01 0x3c 0x02 0x01 0x3c 0x03 0x01 0x3c 0x04 0x01 0x3c 0x05 0x01 0x3c 0x06 0x01 0x3c 0x07 0x01 0x3c 0x08 0x01 0x3c 0x09 0x01 0x3c 0x0a 0x01 0x3c 0x0b 0x01 0x3c 0x0c 0x01 0x3c 0x0d 0x01 0x3c 0x0e 0x01>;
				dma-names = "rx1", "rx2", "rx3", "rx4", "rx5", "rx6", "rx7", "rx8", "rx9", "rx10", "rx11", "rx12", "rx13", "rx14", "rx15", "tx1", "tx2", "tx3", "tx4", "tx5", "tx6", "tx7", "tx8", "tx9", "tx10", "tx11", "tx12", "tx13", "tx14", "tx15";
			};

			usb-phy@47401b00 {
				compatible = "ti,am335x-usb-phy";
				reg = <0x47401b00 0x100>;
				reg-names = "phy";
				status = "okay";
				ti,ctrl_mod = <0x3a>;
				linux,phandle = <0x3d>;
				phandle = <0x3d>;
			};

			usb@47401800 {
				compatible = "ti,musb-am33xx";
				status = "okay";
				reg = <0x47401c00 0x400 0x47401800 0x200>;
				reg-names = "mc", "control";
				interrupts = <0x13>;
				interrupt-names = "mc";
				dr_mode = "host";
				mentor,multipoint = <0x01>;
				mentor,num-eps = <0x10>;
				mentor,ram-bits = <0x0c>;
				mentor,power = <0x1f4>;
				phys = <0x3d>;
				dmas = <0x3c 0x0f 0x00 0x3c 0x10 0x00 0x3c 0x11 0x00 0x3c 0x12 0x00 0x3c 0x13 0x00 0x3c 0x14 0x00 0x3c 0x15 0x00 0x3c 0x16 0x00 0x3c 0x17 0x00 0x3c 0x18 0x00 0x3c 0x19 0x00 0x3c 0x1a 0x00 0x3c 0x1b 0x00 0x3c 0x1c 0x00 0x3c 0x1d 0x00 0x3c 0x0f 0x01 0x3c 0x10 0x01 0x3c 0x11 0x01 0x3c 0x12 0x01 0x3c 0x13 0x01 0x3c 0x14 0x01 0x3c 0x15 0x01 0x3c 0x16 0x01 0x3c 0x17 0x01 0x3c 0x18 0x01 0x3c 0x19 0x01 0x3c 0x1a 0x01 0x3c 0x1b 0x01 0x3c 0x1c 0x01 0x3c 0x1d 0x01>;
				dma-names = "rx1", "rx2", "rx3", "rx4", "rx5", "rx6", "rx7", "rx8", "rx9", "rx10", "rx11", "rx12", "rx13", "rx14", "rx15", "tx1", "tx2", "tx3", "tx4", "tx5", "tx6", "tx7", "tx8", "tx9", "tx10", "tx11", "tx12", "tx13", "tx14", "tx15";
			};

			dma-controller@47402000 {
				compatible = "ti,am3359-cppi41";
				reg = <0x47400000 0x1000 0x47402000 0x1000 0x47403000 0x1000 0x47404000 0x4000>;
				reg-names = "glue", "controller", "scheduler", "queuemgr";
				interrupts = <0x11>;
				interrupt-names = "glue";
				#dma-cells = <0x02>;
				#dma-channels = <0x1e>;
				#dma-requests = <0x100>;
				status = "okay";
				linux,phandle = <0x3c>;
				phandle = <0x3c>;
			};
		};

		epwmss@48300000 {
			compatible = "ti,am33xx-pwmss";
			reg = <0x48300000 0x10>;
			ti,hwmods = "epwmss0";
			#address-cells = <0x01>;
			#size-cells = <0x01>;
			status = "disabled";
			ranges = <0x48300100 0x48300100 0x80 0x48300180 0x48300180 0x80 0x48300200 0x48300200 0x80>;

			ecap@48300100 {
				compatible = "ti,am33xx-ecap";
				#pwm-cells = <0x03>;
				reg = <0x48300100 0x80>;
				ti,hwmods = "ecap0";
				status = "disabled";
			};

			ehrpwm@48300200 {
				compatible = "ti,am33xx-ehrpwm";
				#pwm-cells = <0x03>;
				reg = <0x48300200 0x80>;
				ti,hwmods = "ehrpwm0";
				status = "disabled";
			};
		};

		epwmss@48302000 {
			compatible = "ti,am33xx-pwmss";
			reg = <0x48302000 0x10>;
			ti,hwmods = "epwmss1";
			#address-cells = <0x01>;
			#size-cells = <0x01>;
			status = "disabled";
			ranges = <0x48302100 0x48302100 0x80 0x48302180 0x48302180 0x80 0x48302200 0x48302200 0x80>;

			ecap@48302100 {
				compatible = "ti,am33xx-ecap";
				#pwm-cells = <0x03>;
				reg = <0x48302100 0x80>;
				ti,hwmods = "ecap1";
				status = "disabled";
			};

			ehrpwm@48302200 {
				compatible = "ti,am33xx-ehrpwm";
				#pwm-cells = <0x03>;
				reg = <0x48302200 0x80>;
				ti,hwmods = "ehrpwm1";
				status = "disabled";
			};
		};

		epwmss@48304000 {
			compatible = "ti,am33xx-pwmss";
			reg = <0x48304000 0x10>;
			ti,hwmods = "epwmss2";
			#address-cells = <0x01>;
			#size-cells = <0x01>;
			status = "okay";
			ranges = <0x48304100 0x48304100 0x80 0x48304180 0x48304180 0x80 0x48304200 0x48304200 0x80>;

			ecap@48304100 {
				compatible = "ti,am33xx-ecap";
				#pwm-cells = <0x03>;
				reg = <0x48304100 0x80>;
				ti,hwmods = "ecap2";
				status = "okay";
				pinctrl-names = "default", "sleep";
				pinctrl-0 = <0x3e>;
				pinctrl-1 = <0x3f>;
				linux,phandle = <0x58>;
				phandle = <0x58>;
			};

			ehrpwm@48304200 {
				compatible = "ti,am33xx-ehrpwm";
				#pwm-cells = <0x03>;
				reg = <0x48304200 0x80>;
				ti,hwmods = "ehrpwm2";
				status = "disabled";
			};
		};

		ethernet@4a100000 {
			compatible = "ti,cpsw";
			ti,hwmods = "cpgmac0";
			clocks = <0x40 0x41>;
			clock-names = "fck", "cpts";
			cpdma_channels = <0x08>;
			ale_entries = <0x400>;
			bd_ram_size = <0x2000>;
			no_bd_ram = <0x00>;
			rx_descs = <0x40>;
			mac_control = <0x20>;
			slaves = <0x02>;
			active_slave = <0x00>;
			cpts_clock_mult = <0x80000000>;
			cpts_clock_shift = <0x1d>;
			reg = <0x4a100000 0x800 0x4a101200 0x100>;
			#address-cells = <0x01>;
			#size-cells = <0x01>;
			interrupt-parent = <0x01>;
			interrupts = <0x28 0x29 0x2a 0x2b>;
			ranges;
			pinctrl-names = "default", "sleep";
			pinctrl-0 = <0x42>;
			pinctrl-1 = <0x43>;
			dual_emac = <0x00>;
			status = "okay";

			mdio@4a101000 {
				compatible = "ti,davinci_mdio";
				#address-cells = <0x01>;
				#size-cells = <0x00>;
				ti,hwmods = "davinci_mdio";
				bus_freq = <0xf4240>;
				reg = <0x4a101000 0x100>;
				pinctrl-names = "default", "sleep";
				pinctrl-0 = <0x44>;
				pinctrl-1 = <0x45>;
				status = "okay";
				linux,phandle = <0x46>;
				phandle = <0x46>;
			};

			slave@4a100200 {
				mac-address = [00 00 00 00 00 00];
				phy_id = <0x46 0x00>;
				phy-mode = "rgmii-id";
			};

			slave@4a100300 {
				mac-address = [00 00 00 00 00 00];
				phy_id = <0x46 0x02>;
				phy-mode = "rgmii-id";
			};

			cpsw-phy-sel@44e10650 {
				compatible = "ti,am3352-cpsw-phy-sel";
				reg = <0x44e10650 0x04>;
				reg-names = "gmii-sel";
			};
		};

		ocmcram@40300000 {
			compatible = "ti,am3352-ocmcram";
			reg = <0x40300000 0x10000>;
			ti,hwmods = "ocmcram";
		};

		wkup_m3@44d00000 {
			compatible = "ti,am3353-wkup-m3";
			reg = <0x44d00000 0x4000 0x44d80000 0x2000 0x44e11324 0x24>;
			reg-names = "m3_umem", "m3_dmem", "ipc_regs";
			interrupts = <0x4e>;
			ti,hwmods = "wkup_m3";
			ti,no-reset-on-init;
			mboxes = <0x47 0x48>;
			ti,scale-data-fw = "am335x-evm-scale-data.bin";
		};

		pruss@4a300000 {
			compatible = "ti,am335x-pruss";
			ti,hwmods = "pruss";
			reg = <0x4a300000 0x2000 0x4a302000 0x2000 0x4a310000 0x3000 0x4a320000 0x2000 0x4a326000 0x2000>;
			reg-names = "dram0", "dram1", "shrdram2", "intc", "cfg";
			interrupts = <0x14 0x15 0x16 0x17 0x18 0x19 0x1a 0x1b>;
			#address-cells = <0x01>;
			#size-cells = <0x01>;
			ranges;

			pru@4a334000 {
				compatible = "ti,pru-rproc";
				reg = <0x4a334000 0x2000 0x4a322000 0x400 0x4a322400 0x100>;
				reg-names = "iram", "control", "debug";
				mboxes = <0x47 0x49>;
			};

			pru@4a338000 {
				compatible = "ti,pru-rproc";
				reg = <0x4a338000 0x2000 0x4a324000 0x400 0x4a324400 0x100>;
				reg-names = "iram", "control", "debug";
				mboxes = <0x47 0x4a>;
			};
		};

		elm@48080000 {
			compatible = "ti,am3352-elm";
			reg = <0x48080000 0x2000>;
			interrupts = <0x04>;
			ti,hwmods = "elm";
			status = "okay";
			linux,phandle = <0x4f>;
			phandle = <0x4f>;
		};

		lcdc@4830e000 {
			compatible = "ti,am33xx-tilcdc";
			reg = <0x4830e000 0x1000>;
			interrupt-parent = <0x01>;
			interrupts = <0x24>;
			ti,hwmods = "lcdc";
			status = "okay";
			pinctrl-names = "default", "sleep";
			pinctrl-0 = <0x4b>;
			pinctrl-1 = <0x4c>;
		};

		tscadc@44e0d000 {
			compatible = "ti,am3359-tscadc";
			reg = <0x44e0d000 0x1000>;
			interrupt-parent = <0x01>;
			interrupts = <0x10>;
			ti,hwmods = "adc_tsc";
			status = "disabled";

			tsc {
				compatible = "ti,am3359-tsc";
			};

			adc {
				#io-channel-cells = <0x01>;
				compatible = "ti,am3359-adc";
			};
		};

		gpmc@50000000 {
			compatible = "ti,am3352-gpmc";
			ti,hwmods = "gpmc";
			ti,no-idle-on-init;
			reg = <0x50000000 0x2000>;
			interrupts = <0x64>;
			gpmc,num-cs = <0x07>;
			gpmc,num-waitpins = <0x02>;
			#address-cells = <0x02>;
			#size-cells = <0x01>;
			status = "okay";
			pinctrl-names = "default", "sleep";
			pinctrl-0 = <0x4d>;
			pinctrl-1 = <0x4e>;
			ranges = <0x00 0x00 0x8000000 0x10000000>;

			nand@0,0 {
				reg = <0x00 0x00 0x00>;
				ti,nand-ecc-opt = "bch8";
				ti,elm-id = <0x4f>;
				nand-bus-width = <0x08>;
				gpmc,device-width = <0x01>;
				gpmc,sync-clk-ps = <0x00>;
				gpmc,cs-on-ns = <0x00>;
				gpmc,cs-rd-off-ns = <0x2c>;
				gpmc,cs-wr-off-ns = <0x2c>;
				gpmc,adv-on-ns = <0x06>;
				gpmc,adv-rd-off-ns = <0x22>;
				gpmc,adv-wr-off-ns = <0x2c>;
				gpmc,we-on-ns = <0x00>;
				gpmc,we-off-ns = <0x28>;
				gpmc,oe-on-ns = <0x00>;
				gpmc,oe-off-ns = <0x36>;
				gpmc,access-ns = <0x40>;
				gpmc,rd-cycle-ns = <0x52>;
				gpmc,wr-cycle-ns = <0x52>;
				gpmc,wait-on-read = "true";
				gpmc,wait-on-write = "true";
				gpmc,bus-turnaround-ns = <0x00>;
				gpmc,cycle2cycle-delay-ns = <0x00>;
				gpmc,clk-activation-ns = <0x00>;
				gpmc,wait-monitoring-ns = <0x00>;
				gpmc,wr-access-ns = <0x28>;
				gpmc,wr-data-mux-bus-ns = <0x00>;
				#address-cells = <0x01>;
				#size-cells = <0x01>;

				partition@0 {
					label = "NAND.SPL";
					reg = <0x00 0x20000>;
				};

				partition@1 {
					label = "NAND.SPL.backup1";
					reg = <0x20000 0x20000>;
				};

				partition@2 {
					label = "NAND.SPL.backup2";
					reg = <0x40000 0x20000>;
				};

				partition@3 {
					label = "NAND.SPL.backup3";
					reg = <0x60000 0x20000>;
				};

				partition@4 {
					label = "NAND.u-boot-spl-os";
					reg = <0x80000 0x40000>;
				};

				partition@5 {
					label = "NAND.u-boot";
					reg = <0xc0000 0x100000>;
				};

				partition@6 {
					label = "NAND.u-boot-env";
					reg = <0x1c0000 0x20000>;
				};

				partition@7 {
					label = "NAND.u-boot-env.backup1";
					reg = <0x1e0000 0x20000>;
				};

				partition@8 {
					label = "NAND.kernel";
					reg = <0x200000 0x800000>;
				};

				partition@9 {
					label = "NAND.file-system";
					reg = <0xa00000 0x3f600000>;
				};
			};
		};

		sham@53100000 {
			compatible = "ti,omap4-sham";
			ti,hwmods = "sham";
			reg = <0x53100000 0x200>;
			interrupts = <0x6d>;
			dmas = <0x24 0x24>;
			dma-names = "rx";
			status = "okay";
		};

		aes@53500000 {
			compatible = "ti,omap4-aes";
			ti,hwmods = "aes";
			reg = <0x53500000 0xa0>;
			interrupts = <0x67>;
			dmas = <0x24 0x06 0x24 0x05>;
			dma-names = "tx", "rx";
			status = "okay";
		};

		mcasp@48038000 {
			compatible = "ti,am33xx-mcasp-audio";
			ti,hwmods = "mcasp0";
			reg = <0x48038000 0x2000 0x46000000 0x400000>;
			reg-names = "mpu", "dat";
			interrupts = <0x50 0x51>;
			interrupts-names = "tx", "rx";
			status = "okay";
			dmas = <0x24 0x08 0x24 0x09>;
			dma-names = "tx", "rx";
			pinctrl-names = "default", "sleep";
			pinctrl-0 = <0x50>;
			pinctrl-1 = <0x51>;
			op-mode = <0x00>;
			tdm-slots = <0x02>;
			serial-dir = <0x01 0x02 0x00 0x00 0x00 0x00 0x00 0x00 0x00 0x00 0x00 0x00 0x00 0x00 0x00 0x00>;
			tx-num-evt = <0x20>;
			rx-num-evt = <0x20>;
			linux,phandle = <0x5a>;
			phandle = <0x5a>;
		};

		mcasp@4803C000 {
			compatible = "ti,am33xx-mcasp-audio";
			ti,hwmods = "mcasp1";
			reg = <0x4803c000 0x2000 0x46400000 0x400000>;
			reg-names = "mpu", "dat";
			interrupts = <0x52 0x53>;
			interrupts-names = "tx", "rx";
			status = "disabled";
			dmas = <0x24 0x0a 0x24 0x0b>;
			dma-names = "tx", "rx";
		};

		rng@48310000 {
			compatible = "ti,omap4-rng";
			ti,hwmods = "rng";
			reg = <0x48310000 0x2000>;
			interrupts = <0x6f>;
		};

		sgx@0x56000000 {
			compatible = "ti,sgx";
			ti,hwmods = "gfx";
			reg = <0x56000000 0x1000000>;
			interrupts = <0x25>;
		};
	};

	buzzer {
		compatible = "ti,am335x-buzzer";
		gpios = <0x52 0x1c 0x01>;
		pinctrl-names = "default";
		pinctrl-0 = <0x53>;
		status = "okay";
	};

	gprs {
		compatible = "ti,am335x-gprs";
		gpios = <0x54 0x12 0x00 0x54 0x04 0x01>;
		pinctrl-names = "default";
		pinctrl-0 = <0x55>;
		status = "okay";
	};

	lcd {
		compatible = "ti,am335x-lcd";
		gpios = <0x34 0x0d 0x01>;
		pinctrl-names = "default";
		pinctrl-0 = <0x56>;
		status = "okay";
	};

	led {
		compatible = "ti,am335x-led";
		gpios = <0x52 0x1e 0x01>;
		pinctrl-names = "default";
		pinctrl-0 = <0x57>;
		status = "okay";
	};

	fixedregulator@0 {
		compatible = "regulator-fixed";
		regulator-name = "vbat";
		regulator-min-microvolt = <0x4c4b40>;
		regulator-max-microvolt = <0x4c4b40>;
		regulator-boot-on;
		linux,phandle = <0x2f>;
		phandle = <0x2f>;
	};

	fixedregulator@1 {
		compatible = "regulator-fixed";
		regulator-name = "lis3_reg";
		regulator-boot-on;
	};

	volume_keys@0 {
		compatible = "gpio-keys";
		#address-cells = <0x01>;
		#size-cells = <0x00>;
		autorepeat;

		switch@9 {
			label = "volume-up";
			linux,code = <0x73>;
			gpios = <0x54 0x02 0x01>;
			gpio-key,wakeup;
		};

		switch@10 {
			label = "volume-down";
			linux,code = <0x72>;
			gpios = <0x54 0x03 0x01>;
			gpio-key,wakeup;
		};
	};

	backlight {
		compatible = "pwm-backlight";
		pwms = <0x58 0x00 0xc350 0x00>;
		brightness-levels = <0x00 0x20 0x40 0x60 0x80 0x9f 0xbf 0xdf 0xff>;
		default-brightness-level = <0x08>;
		gpios = <0x34 0x11 0x00>;
	};

	panel {
		compatible = "ti,tilcdc,panel";
		status = "okay";

		panel-info {
			ac-bias = <0xff>;
			ac-bias-intrpt = <0x00>;
			dma-burst-sz = <0x10>;
			bpp = <0x20>;
			fdd = <0x80>;
			sync-edge = <0x00>;
			sync-ctrl = <0x01>;
			raster-order = <0x00>;
			fifo-th = <0x00>;
		};

		display-timings {

			800x480p62 {
				clock-frequency = <0x1c9c380>;
				hactive = <0x320>;
				vactive = <0x1e0>;
				hfront-porch = <0x27>;
				hback-porch = <0x27>;
				hsync-len = <0x2f>;
				vback-porch = <0x1d>;
				vfront-porch = <0x0d>;
				vsync-len = <0x02>;
				hsync-active = <0x01>;
				vsync-active = <0x01>;
			};
		};
	};

	kim {
		compatible = "kim";
		nshutdown_gpio = <0x75>;
		dev_name = "/dev/ttyO1";
		flow_cntrl = <0x01>;
		baud_rate = <0x2dc6c0>;
	};

	btwilink {
		compatible = "btwilink";
	};

	sound {
		compatible = "ti,da830-evm-audio";
		ti,model = "AM335x-EVM";
		ti,audio-codec = <0x59>;
		ti,mcasp-controller = <0x5a>;
		ti,codec-clock-rate = <0x16e3600>;
		ti,audio-routing = "Headphone Jack", "HPLOUT", "Headphone Jack", "HPROUT", "Line Out", "LLOUT", "Line Out", "RLOUT", "MIC3L", "Mic Bias 2V", "MIC3R", "Mic Bias 2V", "Mic Bias 2V", "Mic Jack", "LINE1L", "Line In", "LINE2L", "Line In", "LINE1R", "Line In", "LINE2R", "Line In";
	};
};
